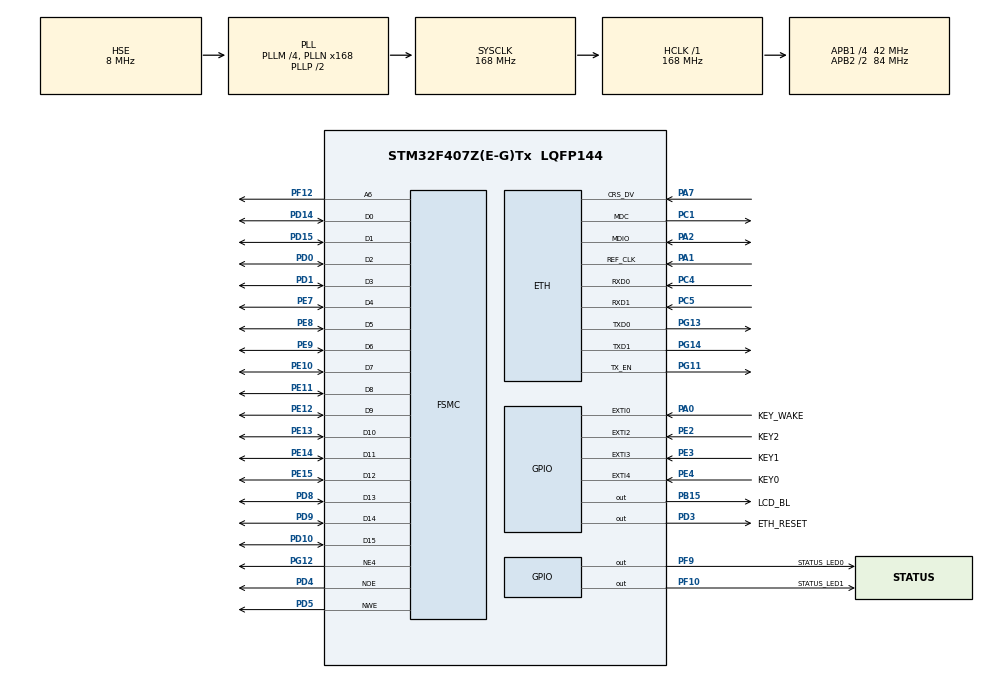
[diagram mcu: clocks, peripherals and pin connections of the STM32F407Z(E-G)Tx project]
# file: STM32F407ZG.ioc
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ETH.MediaInterface=ETH_MEDIA_INTERFACE_RMII
ETH.PHY_Name_RMII=userPHY
ETH.PHY_SR=31
ETH.PHY_User_Name=LAN8720A
ETH.PhyAddress=0
ETH.RxMode=ETH_RXINTERRUPT_MODE
FSMC.AccessMode4=FSMC_ACCESS_MODE_A
FSMC.AddressSetupTime4=0xf
FSMC.BusTurnAroundDuration4=0
FSMC.DataSetupTime4=60
FSMC.ExtendedAddressSetupTime4=0
FSMC.ExtendedBusTurnAroundDuration4=15
FSMC.ExtendedDataSetupTime4=3
FSMC.ExtendedMode4=FSMC_EXTENDED_MODE_ENABLE
Mcu.Family=STM32F4
Mcu.Name=STM32F407Z(E-G)Tx
Mcu.Package=LQFP144
NVIC.ETH_IRQn=true\:5\:0\:true\:false\:true\:false\:true
NVIC.PriorityGroup=NVIC_PRIORITYGROUP_4
NVIC.TIM7_IRQn=true\:0\:0\:false\:false\:true\:false\:true
NVIC.TimeBase=TIM7_IRQn
NVIC.TimeBaseIP=TIM7
PA0-WKUP.GPIO_Label=KEY_WAKE
PA0-WKUP.GPIO_PuPd=GPIO_PULLDOWN
PA0-WKUP.Signal=GPXTI0
PA1.Mode=RMII
PA1.Signal=ETH_REF_CLK
PA13.Mode=JTAG_5_pins
PA13.Signal=SYS_JTMS-SWDIO
PA14.Mode=JTAG_5_pins
PA14.Signal=SYS_JTCK-SWCLK
PA15.Mode=JTAG_5_pins
PA15.Signal=SYS_JTDI
PA2.Mode=RMII
PA2.Signal=ETH_MDIO
PA7.Mode=RMII
PA7.Signal=ETH_CRS_DV
PB15.GPIO_Label=LCD_BL
PB15.GPIO_PuPd=GPIO_PULLUP
PB15.Signal=GPIO_Output
PB3.Mode=JTAG_5_pins
PB3.Signal=SYS_JTDO-SWO
PB4.Mode=JTAG_5_pins
PB4.Signal=SYS_JTRST
PC1.Mode=RMII
PC1.Signal=ETH_MDC
PC4.Mode=RMII
PC4.Signal=ETH_RXD0
PC5.Mode=RMII
PC5.Signal=ETH_RXD1
PD0.Signal=FSMC_D2_DA2
PD1.Signal=FSMC_D3_DA3
PD10.Signal=FSMC_D15_DA15
PD14.Signal=FSMC_D0_DA0
PD15.Signal=FSMC_D1_DA1
PD3.GPIO_Label=ETH_RESET
PD3.GPIO_ModeDefaultOutputPP=GPIO_MODE_OUTPUT_PP
PD3.PinState=GPIO_PIN_SET
PD3.Signal=GPIO_Output
PD4.Signal=FSMC_NOE
PD5.Signal=FSMC_NWE
PD8.Signal=FSMC_D13_DA13
PD9.Signal=FSMC_D14_DA14
PE10.Signal=FSMC_D7_DA7
PE11.Signal=FSMC_D8_DA8
PE12.Signal=FSMC_D9_DA9
PE13.Signal=FSMC_D10_DA10
PE14.Signal=FSMC_D11_DA11
PE15.Signal=FSMC_D12_DA12
PE2.GPIO_Label=KEY2
PE2.GPIO_ModeDefaultEXTI=GPIO_MODE_IT_FALLING
PE2.GPIO_PuPd=GPIO_PULLUP
PE2.Signal=GPXTI2
PE3.GPIO_Label=KEY1
PE3.GPIO_ModeDefaultEXTI=GPIO_MODE_IT_FALLING
PE3.GPIO_PuPd=GPIO_PULLUP
PE3.Signal=GPXTI3
PE4.GPIO_Label=KEY0
PE4.GPIO_ModeDefaultEXTI=GPIO_MODE_IT_FALLING
PE4.GPIO_PuPd=GPIO_PULLUP
PE4.Signal=GPXTI4
PE7.Signal=FSMC_D4_DA4
PE8.Signal=FSMC_D5_DA5
PE9.Signal=FSMC_D6_DA6
PF10.GPIO_Label=STATUS_LED1
PF10.GPIO_ModeDefaultOutputPP=GPIO_MODE_OUTPUT_OD
PF10.PinState=GPIO_PIN_SET
PF10.Signal=GPIO_Output
PF12.Signal=FSMC_A6
PF9.GPIO_Label=STATUS_LED0
PF9.GPIO_ModeDefaultOutputPP=GPIO_MODE_OUTPUT_OD
PF9.PinState=GPIO_PIN_SET
PF9.Signal=GPIO_Output
PG11.Mode=RMII
PG11.Signal=ETH_TX_EN
PG12.Mode=NorPsramChipSelect4_4
PG12.Signal=FSMC_NE4
PG13.Mode=RMII
PG13.Signal=ETH_TXD0
PG14.Mode=RMII
PG14.Signal=ETH_TXD1
PH0-OSC_IN.Mode=HSE-External-Oscillator
PH0-OSC_IN.Signal=RCC_OSC_IN
PH1-OSC_OUT.Mode=HSE-External-Oscillator
PH1-OSC_OUT.Signal=RCC_OSC_OUT
ProjectManager.HeapSize=0x200
ProjectManager.StackSize=0x400
ProjectManager.TargetToolchain=MDK-ARM V5
RCC.48MHZClocksFreq_Value=84000000
RCC.AHBFreq_Value=168000000
RCC.APB1CLKDivider=RCC_HCLK_DIV4
RCC.APB1Freq_Value=42000000
RCC.APB1TimFreq_Value=84000000
RCC.APB2CLKDivider=RCC_HCLK_DIV2
RCC.APB2Freq_Value=84000000
RCC.APB2TimFreq_Value=168000000
RCC.CortexFreq_Value=168000000
RCC.HCLKFreq_Value=168000000
RCC.HSE_VALUE=8000000
RCC.HSI_VALUE=16000000
RCC.LSE_VALUE=32768
RCC.PLLM=4
RCC.PLLN=168
RCC.PLLSourceVirtual=RCC_PLLSOURCE_HSE
RCC.SYSCLKFreq_VALUE=168000000
RCC.SYSCLKSource=RCC_SYSCLKSOURCE_PLLCLK
RCC.VCOOutputFreq_Value=336000000
SH.FSMC_A6.0=FSMC_A6,A6_4
SH.FSMC_D0_DA0.0=FSMC_D0,16b-d4
SH.FSMC_D10_DA10.0=FSMC_D10,16b-d4
SH.FSMC_D11_DA11.0=FSMC_D11,16b-d4
SH.FSMC_D12_DA12.0=FSMC_D12,16b-d4
SH.FSMC_D13_DA13.0=FSMC_D13,16b-d4
SH.FSMC_D14_DA14.0=FSMC_D14,16b-d4
SH.FSMC_D15_DA15.0=FSMC_D15,16b-d4
SH.FSMC_D1_DA1.0=FSMC_D1,16b-d4
SH.FSMC_D2_DA2.0=FSMC_D2,16b-d4
SH.FSMC_D3_DA3.0=FSMC_D3,16b-d4
SH.FSMC_D4_DA4.0=FSMC_D4,16b-d4
SH.FSMC_D5_DA5.0=FSMC_D5,16b-d4
SH.FSMC_D6_DA6.0=FSMC_D6,16b-d4
SH.FSMC_D7_DA7.0=FSMC_D7,16b-d4
SH.FSMC_D8_DA8.0=FSMC_D8,16b-d4
SH.FSMC_D9_DA9.0=FSMC_D9,16b-d4
SH.FSMC_NOE.0=FSMC_NOE,Lcd4
SH.FSMC_NWE.0=FSMC_NWE,Lcd4
VP_SYS_VS_tim7.Mode=TIM7
board=custom

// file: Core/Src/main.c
/* USER CODE BEGIN Header */
/**
  ******************************************************************************
  * @file           : main.c
  * @brief          : Main program body
  ******************************************************************************
  * @attention
  *
  * <h2><center>&copy; Copyright (c) 2020 STMicroelectronics.
  * All rights reserved.</center></h2>
  *
  * This software component is licensed by ST under BSD 3-Clause license,
  * the "License"; You may not use this file except in compliance with the
  * License. You may obtain a copy of the License at:
  *                        opensource.org/licenses/BSD-3-Clause
  *
  ******************************************************************************
  */
/* USER CODE END Header */

#include "main.h"

/* USER CODE BEGIN Includes */
#include "app.h"
/* USER CODE END Includes */

ETH_HandleTypeDef heth;

SRAM_HandleTypeDef hsram4;

void SystemClock_Config(void);
static void MX_GPIO_Init(void);
static void MX_FSMC_Init(void);
void MX_ETH_Init(void);

int main(void)
{

  /* MCU Configuration--------------------------------------------------------*/

  /* Reset of all peripherals, Initializes the Flash interface and the Systick. */
  HAL_Init();

  /* Configure the system clock */
  SystemClock_Config();

  /* Initialize all configured peripherals */
  MX_GPIO_Init();
  MX_FSMC_Init();
  /* USER CODE BEGIN 2 */
  App_Start();
  /* USER CODE END 2 */

  /* Infinite loop */
  while (1)
  {

  }
}

void SystemClock_Config(void)
{
  RCC_OscInitTypeDef RCC_OscInitStruct = {0};
  RCC_ClkInitTypeDef RCC_ClkInitStruct = {0};

  /** Configure the main internal regulator output voltage
  */
  __HAL_RCC_PWR_CLK_ENABLE();
  __HAL_PWR_VOLTAGESCALING_CONFIG(PWR_REGULATOR_VOLTAGE_SCALE1);
  /** Initializes the CPU, AHB and APB busses clocks
  */
  RCC_OscInitStruct.OscillatorType = RCC_OSCILLATORTYPE_HSE;
  RCC_OscInitStruct.HSEState = RCC_HSE_ON;
  RCC_OscInitStruct.PLL.PLLState = RCC_PLL_ON;
  RCC_OscInitStruct.PLL.PLLSource = RCC_PLLSOURCE_HSE;
  RCC_OscInitStruct.PLL.PLLM = 4;
  RCC_OscInitStruct.PLL.PLLN = 168;
  RCC_OscInitStruct.PLL.PLLP = RCC_PLLP_DIV2;
  RCC_OscInitStruct.PLL.PLLQ = 4;
  if (HAL_RCC_OscConfig(&RCC_OscInitStruct) != HAL_OK)
  {
    Error_Handler();
  }
  /** Initializes the CPU, AHB and APB busses clocks
  */
  RCC_ClkInitStruct.ClockType = RCC_CLOCKTYPE_HCLK|RCC_CLOCKTYPE_SYSCLK
                              |RCC_CLOCKTYPE_PCLK1|RCC_CLOCKTYPE_PCLK2;
  RCC_ClkInitStruct.SYSCLKSource = RCC_SYSCLKSOURCE_PLLCLK;
  RCC_ClkInitStruct.AHBCLKDivider = RCC_SYSCLK_DIV1;
  RCC_ClkInitStruct.APB1CLKDivider = RCC_HCLK_DIV4;
  RCC_ClkInitStruct.APB2CLKDivider = RCC_HCLK_DIV2;

  if (HAL_RCC_ClockConfig(&RCC_ClkInitStruct, FLASH_LATENCY_5) != HAL_OK)
  {
    Error_Handler();
  }
}

void MX_ETH_Init(void)
{

  heth.Instance = ETH;
  heth.Init.AutoNegotiation = ETH_AUTONEGOTIATION_ENABLE;
  heth.Init.PhyAddress = LAN8720A_PHY_ADDRESS;
  heth.Init.MACAddr[0] =   0x00;
  heth.Init.MACAddr[1] =   0x80;
  heth.Init.MACAddr[2] =   0xE1;
  heth.Init.MACAddr[3] =   0x00;
  heth.Init.MACAddr[4] =   0x00;
  heth.Init.MACAddr[5] =   0x00;
  heth.Init.RxMode = ETH_RXINTERRUPT_MODE;
  heth.Init.ChecksumMode = ETH_CHECKSUM_BY_HARDWARE;
  heth.Init.MediaInterface = ETH_MEDIA_INTERFACE_RMII;

  if (HAL_ETH_Init(&heth) != HAL_OK)
  {
    Error_Handler();
  }

}

static void MX_GPIO_Init(void)
{
  GPIO_InitTypeDef GPIO_InitStruct = {0};

  /* GPIO Ports Clock Enable */
  __HAL_RCC_GPIOE_CLK_ENABLE();
  __HAL_RCC_GPIOF_CLK_ENABLE();
  __HAL_RCC_GPIOH_CLK_ENABLE();
  __HAL_RCC_GPIOC_CLK_ENABLE();
  __HAL_RCC_GPIOA_CLK_ENABLE();
  __HAL_RCC_GPIOB_CLK_ENABLE();
  __HAL_RCC_GPIOD_CLK_ENABLE();
  __HAL_RCC_GPIOG_CLK_ENABLE();

  /*Configure GPIO pin Output Level */
  HAL_GPIO_WritePin(GPIOF, STATUS_LED0_Pin|STATUS_LED1_Pin, GPIO_PIN_SET);

  /*Configure GPIO pin Output Level */
  HAL_GPIO_WritePin(LCD_BL_GPIO_Port, LCD_BL_Pin, GPIO_PIN_RESET);

  /*Configure GPIO pin Output Level */
  HAL_GPIO_WritePin(ETH_RESET_GPIO_Port, ETH_RESET_Pin, GPIO_PIN_SET);

  /*Configure GPIO pins : KEY2_Pin KEY1_Pin KEY0_Pin */
  GPIO_InitStruct.Pin = KEY2_Pin|KEY1_Pin|KEY0_Pin;
  GPIO_InitStruct.Mode = GPIO_MODE_IT_FALLING;
  GPIO_InitStruct.Pull = GPIO_PULLUP;
  HAL_GPIO_Init(GPIOE, &GPIO_InitStruct);

  /*Configure GPIO pins : STATUS_LED0_Pin STATUS_LED1_Pin */
  GPIO_InitStruct.Pin = STATUS_LED0_Pin|STATUS_LED1_Pin;
  GPIO_InitStruct.Mode = GPIO_MODE_OUTPUT_OD;
  GPIO_InitStruct.Pull = GPIO_NOPULL;
  GPIO_InitStruct.Speed = GPIO_SPEED_FREQ_LOW;
  HAL_GPIO_Init(GPIOF, &GPIO_InitStruct);

  /*Configure GPIO pin : KEY_WAKE_Pin */
  GPIO_InitStruct.Pin = KEY_WAKE_Pin;
  GPIO_InitStruct.Mode = GPIO_MODE_IT_RISING;
  GPIO_InitStruct.Pull = GPIO_PULLDOWN;
  HAL_GPIO_Init(KEY_WAKE_GPIO_Port, &GPIO_InitStruct);

  /*Configure GPIO pin : LCD_BL_Pin */
  GPIO_InitStruct.Pin = LCD_BL_Pin;
  GPIO_InitStruct.Mode = GPIO_MODE_OUTPUT_PP;
  GPIO_InitStruct.Pull = GPIO_PULLUP;
  GPIO_InitStruct.Speed = GPIO_SPEED_FREQ_LOW;
  HAL_GPIO_Init(LCD_BL_GPIO_Port, &GPIO_InitStruct);

  /*Configure GPIO pin : ETH_RESET_Pin */
  GPIO_InitStruct.Pin = ETH_RESET_Pin;
  GPIO_InitStruct.Mode = GPIO_MODE_OUTPUT_PP;
  GPIO_InitStruct.Pull = GPIO_NOPULL;
  GPIO_InitStruct.Speed = GPIO_SPEED_FREQ_LOW;
  HAL_GPIO_Init(ETH_RESET_GPIO_Port, &GPIO_InitStruct);

}

/* FSMC initialization function */
static void MX_FSMC_Init(void)
{

  FSMC_NORSRAM_TimingTypeDef Timing = {0};
  FSMC_NORSRAM_TimingTypeDef ExtTiming = {0};

  /** Perform the SRAM4 memory initialization sequence
  */
  hsram4.Instance = FSMC_NORSRAM_DEVICE;
  hsram4.Extended = FSMC_NORSRAM_EXTENDED_DEVICE;
  /* hsram4.Init */
  hsram4.Init.NSBank = FSMC_NORSRAM_BANK4;
  hsram4.Init.DataAddressMux = FSMC_DATA_ADDRESS_MUX_DISABLE;
  hsram4.Init.MemoryType = FSMC_MEMORY_TYPE_SRAM;
  hsram4.Init.MemoryDataWidth = FSMC_NORSRAM_MEM_BUS_WIDTH_16;
  hsram4.Init.BurstAccessMode = FSMC_BURST_ACCESS_MODE_DISABLE;
  hsram4.Init.WaitSignalPolarity = FSMC_WAIT_SIGNAL_POLARITY_LOW;
  hsram4.Init.WrapMode = FSMC_WRAP_MODE_DISABLE;
  hsram4.Init.WaitSignalActive = FSMC_WAIT_TIMING_BEFORE_WS;
  hsram4.Init.WriteOperation = FSMC_WRITE_OPERATION_ENABLE;
  hsram4.Init.WaitSignal = FSMC_WAIT_SIGNAL_DISABLE;
  hsram4.Init.ExtendedMode = FSMC_EXTENDED_MODE_ENABLE;
  hsram4.Init.AsynchronousWait = FSMC_ASYNCHRONOUS_WAIT_DISABLE;
  hsram4.Init.WriteBurst = FSMC_WRITE_BURST_DISABLE;
  hsram4.Init.PageSize = FSMC_PAGE_SIZE_NONE;
  /* Timing */
  Timing.AddressSetupTime = 0xf;
  Timing.AddressHoldTime = 15;
  Timing.DataSetupTime = 60;
  Timing.BusTurnAroundDuration = 0;
  Timing.CLKDivision = 16;
  Timing.DataLatency = 17;
  Timing.AccessMode = FSMC_ACCESS_MODE_A;
  /* ExtTiming */
  ExtTiming.AddressSetupTime = 0;
  ExtTiming.AddressHoldTime = 15;
  ExtTiming.DataSetupTime = 3;
  ExtTiming.BusTurnAroundDuration = 15;
  ExtTiming.CLKDivision = 16;
  ExtTiming.DataLatency = 17;
  ExtTiming.AccessMode = FSMC_ACCESS_MODE_A;

  if (HAL_SRAM_Init(&hsram4, &Timing, &ExtTiming) != HAL_OK)
  {
    Error_Handler( );
  }

}

 /**
  * @brief  Period elapsed callback in non blocking mode
  * @note   This function is called  when TIM7 interrupt took place, inside
  * HAL_TIM_IRQHandler(). It makes a direct call to HAL_IncTick() to increment
  * a global variable "uwTick" used as application time base.
  * @param  htim : TIM handle
  * @retval None
  */
void HAL_TIM_PeriodElapsedCallback(TIM_HandleTypeDef *htim)
{
  if (htim->Instance == TIM7) {
    HAL_IncTick();
  }
}

void Error_Handler(void)
{
}

/************************ (C) COPYRIGHT STMicroelectronics *****END OF FILE****/
